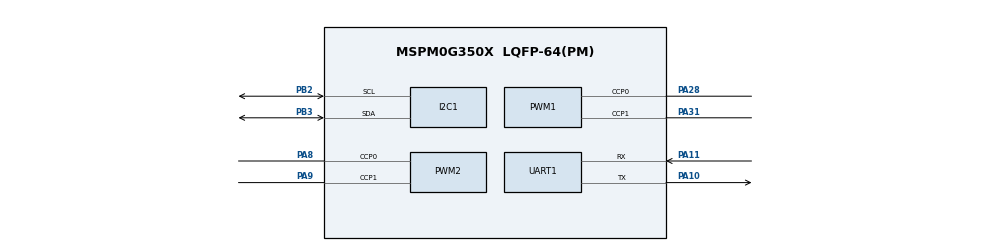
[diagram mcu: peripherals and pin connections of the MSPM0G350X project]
/**
 * @cliArgs --device "MSPM0G350X" --part "Default" --package "LQFP-64(PM)" --product "mspm0_sdk@2.05.00.05"
 * @versions {"tool":"1.24.0+4110"}
 */

/**
 * Import the modules used in this configuration.
 */
const GPIO    = scripting.addModule("/ti/driverlib/GPIO", {}, false);
const GPIO1   = GPIO.addInstance();
const GPIO2   = GPIO.addInstance();
const GPIO3   = GPIO.addInstance();
const GPIO4   = GPIO.addInstance();
const GPIO5   = GPIO.addInstance();
const GPIO6   = GPIO.addInstance();
const GPIO7   = GPIO.addInstance();
const GPIO8   = GPIO.addInstance();
const I2C     = scripting.addModule("/ti/driverlib/I2C", {}, false);
const I2C1    = I2C.addInstance();
const PWM     = scripting.addModule("/ti/driverlib/PWM", {}, false);
const PWM1    = PWM.addInstance();
const PWM2    = PWM.addInstance();
const SYSCTL  = scripting.addModule("/ti/driverlib/SYSCTL");
const SYSTICK = scripting.addModule("/ti/driverlib/SYSTICK");
const TIMER   = scripting.addModule("/ti/driverlib/TIMER", {}, false);
const TIMER1  = TIMER.addInstance();
const UART    = scripting.addModule("/ti/driverlib/UART", {}, false);
const UART1   = UART.addInstance();

/**
 * Write custom configuration values to the imported modules.
 */
const divider7       = system.clockTree["PLL_PDIV"];
divider7.divideValue = 2;

const divider9       = system.clockTree["UDIV"];
divider9.divideValue = 2;

const gate7  = system.clockTree["MFCLKGATE"];
gate7.enable = true;

const multiplier2         = system.clockTree["PLL_QDIV"];
multiplier2.multiplyValue = 5;

const mux8       = system.clockTree["HSCLKMUX"];
mux8.inputSelect = "HSCLKMUX_SYSPLL2X";

GPIO1.$name                         = "CIN";
GPIO1.port                          = "PORTA";
GPIO1.associatedPins.create(2);
GPIO1.associatedPins[0].$name       = "CIN1";
GPIO1.associatedPins[0].assignedPin = "24";
GPIO1.associatedPins[1].$name       = "CIN2";
GPIO1.associatedPins[1].assignedPin = "26";

const Board = scripting.addModule("/ti/driverlib/Board", {}, false);

GPIO2.$name                         = "DIN";
GPIO2.port                          = "PORTB";
GPIO2.associatedPins.create(2);
GPIO2.associatedPins[0].$name       = "DIN1";
GPIO2.associatedPins[0].assignedPin = "24";
GPIO2.associatedPins[1].$name       = "DIN2";
GPIO2.associatedPins[1].assignedPin = "20";

GPIO3.$name                         = "AIN";
GPIO3.port                          = "PORTA";
GPIO3.associatedPins.create(2);
GPIO3.associatedPins[0].$name       = "AIN1";
GPIO3.associatedPins[0].assignedPin = "12";
GPIO3.associatedPins[1].$name       = "AIN2";
GPIO3.associatedPins[1].assignedPin = "7";

GPIO4.$name                         = "BIN";
GPIO4.port                          = "PORTB";
GPIO4.associatedPins.create(2);
GPIO4.associatedPins[0].$name       = "BIN1";
GPIO4.associatedPins[0].assignedPin = "16";
GPIO4.associatedPins[1].$name       = "BIN2";
GPIO4.associatedPins[1].assignedPin = "17";

GPIO5.$name                         = "ENCODERA";
GPIO5.port                          = "PORTA";
GPIO5.associatedPins.create(2);
GPIO5.associatedPins[0].$name       = "E1A";
GPIO5.associatedPins[0].direction   = "INPUT";
GPIO5.associatedPins[0].interruptEn = true;
GPIO5.associatedPins[0].polarity    = "RISE";
GPIO5.associatedPins[0].assignedPin = "13";
GPIO5.associatedPins[1].$name       = "E1B";
GPIO5.associatedPins[1].direction   = "INPUT";
GPIO5.associatedPins[1].interruptEn = true;
GPIO5.associatedPins[1].polarity    = "RISE";
GPIO5.associatedPins[1].assignedPin = "14";

GPIO6.$name                         = "ENCODERC";
GPIO6.port                          = "PORTB";
GPIO6.associatedPins.create(2);
GPIO6.associatedPins[0].$name       = "E3A";
GPIO6.associatedPins[0].direction   = "INPUT";
GPIO6.associatedPins[0].interruptEn = true;
GPIO6.associatedPins[0].polarity    = "RISE";
GPIO6.associatedPins[0].assignedPin = "7";
GPIO6.associatedPins[1].$name       = "E3B";
GPIO6.associatedPins[1].direction   = "INPUT";
GPIO6.associatedPins[1].interruptEn = true;
GPIO6.associatedPins[1].polarity    = "RISE";
GPIO6.associatedPins[1].assignedPin = "6";

GPIO7.$name                         = "OLED";
GPIO7.port                          = "PORTA";
GPIO7.associatedPins.create(2);
GPIO7.associatedPins[0].$name       = "OLED_SCL";
GPIO7.associatedPins[0].assignedPin = "1";
GPIO7.associatedPins[1].$name       = "OLED_SDA";
GPIO7.associatedPins[1].assignedPin = "25";

GPIO8.$name                         = "IR_DH";
GPIO8.port                          = "PORTA";
GPIO8.associatedPins.create(4);
GPIO8.associatedPins[0].$name       = "PIN_0";
GPIO8.associatedPins[0].direction   = "INPUT";
GPIO8.associatedPins[0].assignedPin = "15";
GPIO8.associatedPins[1].$name       = "PIN_1";
GPIO8.associatedPins[1].direction   = "INPUT";
GPIO8.associatedPins[1].assignedPin = "22";
GPIO8.associatedPins[2].$name       = "PIN_2";
GPIO8.associatedPins[2].direction   = "INPUT";
GPIO8.associatedPins[2].assignedPin = "16";
GPIO8.associatedPins[3].$name       = "PIN_3";
GPIO8.associatedPins[3].direction   = "INPUT";
GPIO8.associatedPins[3].assignedPin = "17";

I2C1.$name                             = "I2C_1";
I2C1.basicEnableController             = true;
I2C1.peripheral.sdaPin.$assign         = "PB3";
I2C1.peripheral.sclPin.$assign         = "PB2";
I2C1.sdaPinConfig.hideOutputInversion  = scripting.forceWrite(false);
I2C1.sdaPinConfig.onlyInternalResistor = scripting.forceWrite(false);
I2C1.sdaPinConfig.passedPeripheralType = scripting.forceWrite("Digital");
I2C1.sdaPinConfig.$name                = "ti_driverlib_gpio_GPIOPinGeneric6";
I2C1.sclPinConfig.hideOutputInversion  = scripting.forceWrite(false);
I2C1.sclPinConfig.onlyInternalResistor = scripting.forceWrite(false);
I2C1.sclPinConfig.passedPeripheralType = scripting.forceWrite("Digital");
I2C1.sclPinConfig.$name                = "ti_driverlib_gpio_GPIOPinGeneric7";

PWM1.$name                      = "PWM_0";
PWM1.timerStartTimer            = true;
PWM1.pwmMode                    = "EDGE_ALIGN_UP";
PWM1.timerCount                 = 8000;
PWM1.peripheral.$assign         = "TIMA1";
PWM1.peripheral.ccp0Pin.$assign = "PA28";
PWM1.peripheral.ccp1Pin.$assign = "PA31";
PWM1.PWM_CHANNEL_0.$name        = "ti_driverlib_pwm_PWMTimerCC0";
PWM1.PWM_CHANNEL_1.$name        = "ti_driverlib_pwm_PWMTimerCC1";
PWM1.ccp0PinConfig.$name        = "ti_driverlib_gpio_GPIOPinGeneric4";
PWM1.ccp1PinConfig.$name        = "ti_driverlib_gpio_GPIOPinGeneric5";

PWM2.$name                      = "PWM_1";
PWM2.pwmMode                    = "EDGE_ALIGN_UP";
PWM2.timerCount                 = 8000;
PWM2.peripheral.ccp0Pin.$assign = "PA8";
PWM2.peripheral.ccp1Pin.$assign = "PA9";
PWM2.PWM_CHANNEL_0.$name        = "ti_driverlib_pwm_PWMTimerCC2";
PWM2.PWM_CHANNEL_1.$name        = "ti_driverlib_pwm_PWMTimerCC3";
PWM2.ccp0PinConfig.$name        = "ti_driverlib_gpio_GPIOPinGeneric0";
PWM2.ccp1PinConfig.$name        = "ti_driverlib_gpio_GPIOPinGeneric1";

SYSCTL.forceDefaultClkConfig = true;
SYSCTL.clockTreeEn           = true;

SYSTICK.periodEnable  = true;
SYSTICK.systickEnable = true;
SYSTICK.period        = 16777216;

TIMER1.$name              = "TIMER_0";
TIMER1.timerClkPrescale   = 32;
TIMER1.timerMode          = "PERIODIC";
TIMER1.timerStartTimer    = true;
TIMER1.interrupts         = ["ZERO"];
TIMER1.timerPeriod        = "10 ms";
TIMER1.peripheral.$assign = "TIMG0";

UART1.$name                    = "UART_0";
UART1.profile                  = "CONFIG_PROFILE_1";
UART1.peripheral.rxPin.$assign = "PA11";
UART1.peripheral.txPin.$assign = "PA10";
UART1.txPinConfig.$name        = "ti_driverlib_gpio_GPIOPinGeneric2";
UART1.rxPinConfig.$name        = "ti_driverlib_gpio_GPIOPinGeneric3";

/**
 * Pinmux solution for unlocked pins/peripherals. This ensures that minor changes to the automatic solver in a future
 * version of the tool will not impact the pinmux you originally saw.  These lines can be completely deleted in order to
 * re-solve from scratch.
 */
GPIO1.associatedPins[0].pin.$suggestSolution = "PA24";
GPIO1.associatedPins[1].pin.$suggestSolution = "PA26";
Board.peripheral.$suggestSolution            = "DEBUGSS";
Board.peripheral.swclkPin.$suggestSolution   = "PA20";
Board.peripheral.swdioPin.$suggestSolution   = "PA19";
GPIO2.associatedPins[0].pin.$suggestSolution = "PB24";
GPIO2.associatedPins[1].pin.$suggestSolution = "PB20";
GPIO3.associatedPins[0].pin.$suggestSolution = "PA12";
GPIO3.associatedPins[1].pin.$suggestSolution = "PA7";
GPIO4.associatedPins[0].pin.$suggestSolution = "PB16";
GPIO4.associatedPins[1].pin.$suggestSolution = "PB17";
GPIO5.associatedPins[0].pin.$suggestSolution = "PA13";
GPIO5.associatedPins[1].pin.$suggestSolution = "PA14";
GPIO6.associatedPins[0].pin.$suggestSolution = "PB7";
GPIO6.associatedPins[1].pin.$suggestSolution = "PB6";
GPIO7.associatedPins[0].pin.$suggestSolution = "PA1";
GPIO7.associatedPins[1].pin.$suggestSolution = "PA25";
GPIO8.associatedPins[0].pin.$suggestSolution = "PA15";
GPIO8.associatedPins[1].pin.$suggestSolution = "PA22";
GPIO8.associatedPins[2].pin.$suggestSolution = "PA16";
GPIO8.associatedPins[3].pin.$suggestSolution = "PA17";
I2C1.peripheral.$suggestSolution             = "I2C1";
PWM2.peripheral.$suggestSolution             = "TIMA0";
UART1.peripheral.$suggestSolution            = "UART0";
